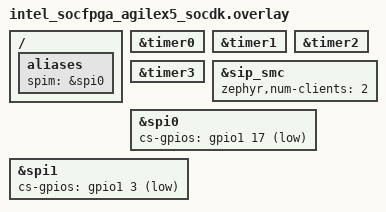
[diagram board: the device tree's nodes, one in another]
/*
 * Copyright (C) 2023 Intel Corporation
 * SPDX-License-Identifier: Apache-2.0
 */

/*
 * The overlay file should be used to enable any
 * dts nodes required by this shell application for this
 * board.
 *
 * Nothing here as of now.
 */

/ {
	aliases {
		spim = &spi0;
	};
};

&timer0 {
	status = "okay";
};

&timer1 {
	status = "okay";
};

&timer2 {
	status = "okay";
};

&timer3 {
	status = "okay";
};

&sip_smc {
	status = "okay";
	zephyr,num-clients = <2>;
};

&spi0 {
	status = "okay";
	/* Can select one or multiple slave select pins.
	 * following are example pins:
	 * gpio1 17 GPIO_ACTIVE_LOW
	 * gpio1 19 GPIO_ACTIVE_LOW
	 * gpio1 23 GPIO_ACTIVE_LOW
	 */
	cs-gpios = <&gpio1 17 GPIO_ACTIVE_LOW>;
};

&spi1 {
	status = "okay";
	/* Can select one or multiple slave select pins.
	 * following are example pins:
	 * gpio0 19 GPIO_ACTIVE_LOW
	 * gpio0 23 GPIO_ACTIVE_LOW
	 * gpio1 3 GPIO_ACTIVE_LOW
	 */
	cs-gpios = <&gpio1 3 GPIO_ACTIVE_LOW>;
};
